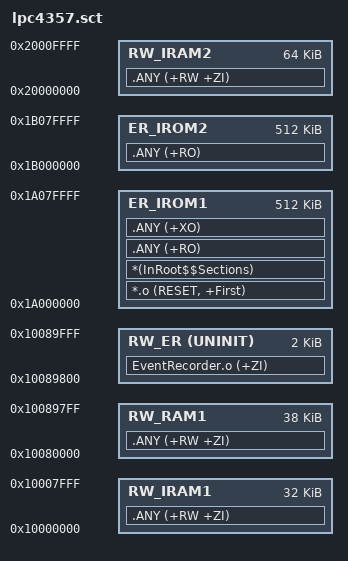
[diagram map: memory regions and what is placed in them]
; *************************************************************
; *** Scatter-Loading Description File generated by uVision ***
; *************************************************************

LR_IROM1 0x1A000000 0x00080000  {    ; load region size_region
  ER_IROM1 0x1A000000 0x00080000  {  ; load address = execution address
   *.o (RESET, +First)
   *(InRoot$$Sections)
   .ANY (+RO)
   .ANY (+XO)
  }
  RW_RAM1 0x10080000 0x00009800  {  ; RW data
   .ANY (+RW +ZI)
  }
  RW_ER 0x10089800 UNINIT 0x00000800  {
    EventRecorder.o (+ZI)
  }
  RW_IRAM1 0x10000000 0x00008000  {
   .ANY (+RW +ZI)
  }
  RW_IRAM2 0x20000000 0x00010000  {
   .ANY (+RW +ZI)
  }
}

LR_IROM2 0x1B000000 0x00080000  {
  ER_IROM2 0x1B000000 0x00080000  {  ; load address = execution address
   .ANY (+RO)
  }
}
